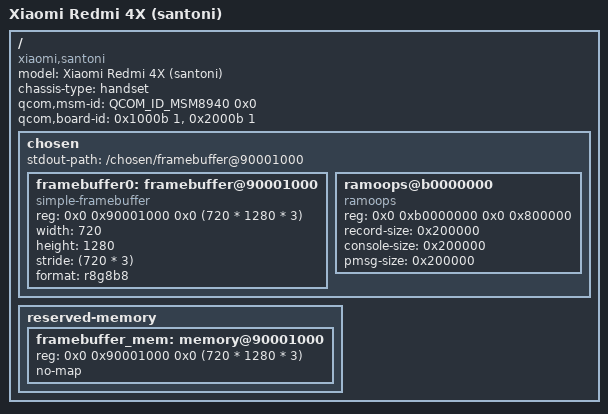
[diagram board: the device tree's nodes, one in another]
// SPDX-License-Identifier: BSD-3-Clause
/*
 * Copyright (c) 2023, Dang Huynh <danct12@riseup.net>
 */

/dts-v1/;

#include "msm8937.dtsi"
#include <dt-bindings/arm/qcom,ids.h>

/ {
	model = "Xiaomi Redmi 4X (santoni)";
	compatible = "xiaomi,santoni", "qcom,msm8940";
	chassis-type = "handset";

	qcom,msm-id = <QCOM_ID_MSM8940 0x0>;
	qcom,board-id = <0x1000b 1>, <0x2000b 1>;

	chosen {
		#address-cells = <2>;
		#size-cells = <2>;
		ranges;

		stdout-path = "/chosen/framebuffer@90001000";

		framebuffer0: framebuffer@90001000 {
			compatible = "simple-framebuffer";
			reg = <0x0 0x90001000 0x0 (720 * 1280 * 3)>;
			width = <720>;
			height = <1280>;
			stride = <(720 * 3)>;
			format = "r8g8b8";
		};

		ramoops@b0000000 {
			compatible = "ramoops";
			reg = <0x0 0xb0000000 0x0 0x800000>;
			record-size = <0x200000>;
			console-size = <0x200000>;
			pmsg-size = <0x200000>;
		};
	};

	reserved-memory {
		framebuffer_mem: memory@90001000 {
			reg = <0x0 0x90001000 0x0 (720 * 1280 * 3)>;
			no-map;
		};
	};
};
